# STM32L4P5 register map
File version: 1.8
CPU: CM4 r0p1, little endian, MPU, FPU, 4 interrupt priority bits
Registers are 32-bit, read-write, reset 0x0 unless marked. A register's access mark holds for its fields unless they carry their own. Offsets are from the block's base; [hi:lo] are bit positions; {n}, {i} and the like mark numbered series; 'fields as' and 'values as' point back to an identical list.

## GPIOA — General-purpose I/Os
Base 0x48000000
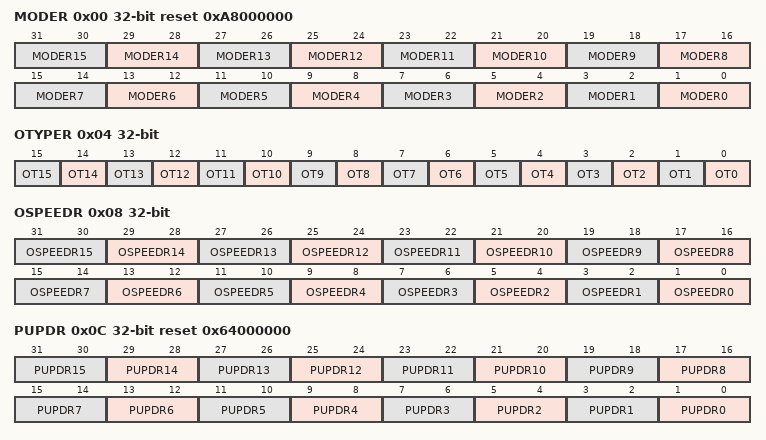
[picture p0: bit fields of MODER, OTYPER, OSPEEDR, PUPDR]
0x00 MODER reset 0xA8000000 — GPIO port mode register
  [2n+1:2n] MODER{n} (n=0..15) — Port x configuration pin {n}
    0=Input mode (reset state); 1=Output (General purpose output mode); 2=Alternate function mode; 3=Analog mode
0x04 OTYPER — GPIO port output type register
  [n] OT{n} (n=0..15) — Port x configuration pin {n}
    0=PushPull (Output push-pull (reset state)); 1=OpenDrain (Output open-drain)
0x08 OSPEEDR — GPIO port output speed register
  [2n+1:2n] OSPEEDR{n} (n=0..15) — Port x configuration pin {n}
    0=LowSpeed; 1=MediumSpeed; 2=HighSpeed; 3=VeryHighSpeed
0x0C PUPDR reset 0x64000000 — GPIO port pull-up/pull-down register
  [2n+1:2n] PUPDR{n} (n=0..15) — Port x configuration pin {n}
    0=Floating (No pull-up, pull-down); 1=PullUp; 2=PullDown
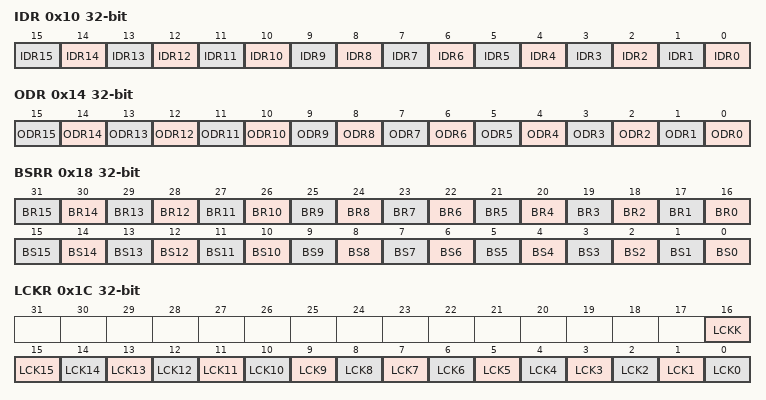
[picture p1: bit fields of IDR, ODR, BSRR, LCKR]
0x10 IDR ro — GPIO port input data register
  [n] IDR{n} (n=0..15) — Port input data pin {n}
    0=Low (Input is logic low); 1=High (Input is logic high)
0x14 ODR — GPIO port output data register
  [n] ODR{n} (n=0..15) — Port output data pin {n}
    0=Low (Set output to logic low); 1=High (Set output to logic high)
0x18 BSRR wo — GPIO port bit set/reset register
  [n+16] BR{n} (n=0..15) — Port x reset pin {n}
    1=Resets the corresponding ODRx bit
  [n] BS{n} (n=0..15) — Port x set pin {n}
    1=Set (Sets the corresponding ODRx bit)
0x1C LCKR — GPIO port configuration lock register
  [16] LCKK — Port x lock bit y (y= 0..15)
    0=NotActive (Port configuration lock key not active); 1=Active (Port configuration lock key active)
  [n] LCK{n} (n=0..15) — Port x lock pin {n}
    0=Unlocked (Port configuration not locked); 1=Locked (Port configuration locked)
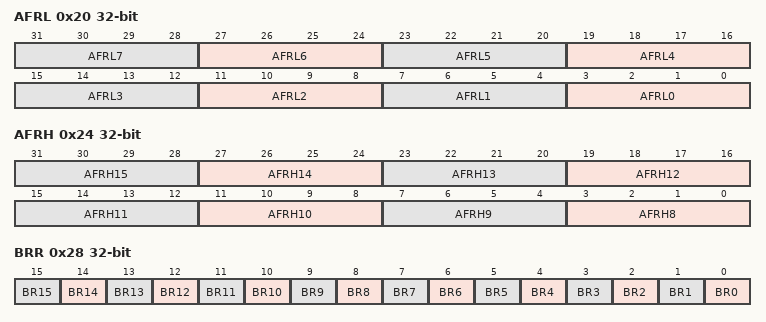
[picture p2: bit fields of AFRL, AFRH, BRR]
0x20 AFRL — GPIO alternate function low register
  [3:0] AFR{x} (x=L0,L1,L2,L3,L4,L5,L6,L7; step 4) — Alternate function selection for port x bit y (y = 0..7)
    {v}=AF{v} (v=0..15)
0x24 AFRH — GPIO alternate function high register
  [3:0] AFR{x} (x=H8,H9,H10,H11,H12,H13,H14,H15; step 4) — Alternate function selection for port x bit y (y = 8..15)
    {v}=AF{v} (v=0..15)
0x28 BRR wo — GPIO port bit reset register
  [n] BR{n} (n=0..15) — Port x reset pin {n}
    0=No action on the corresponding ODx bit; 1=Reset the ODx bit

## GPIOB — General-purpose I/Os
Base 0x48000400
Registers as GPIOA; these are added or differ:
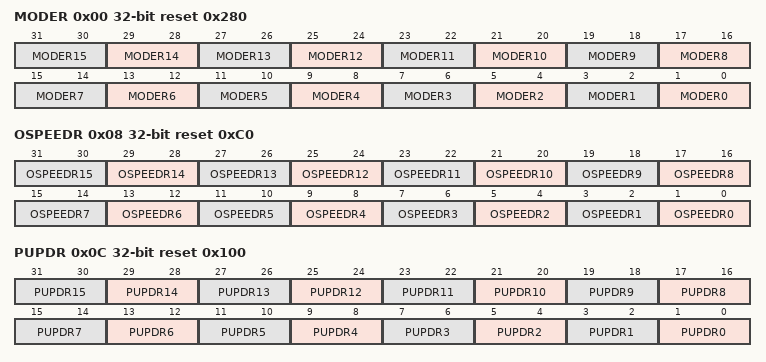
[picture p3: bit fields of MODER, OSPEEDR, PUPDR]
0x00 MODER reset 0x280 — GPIO port mode register
  [2n+1:2n] MODER{n} (n=0..15) — Port x configuration pin {n}
    0=Input mode (reset state); 1=Output (General purpose output mode); 2=Alternate function mode; 3=Analog mode
0x08 OSPEEDR reset 0xC0 — GPIO port output speed register
  [2n+1:2n] OSPEEDR{n} (n=0..15) — Port x configuration pin {n}
    0=LowSpeed; 1=MediumSpeed; 2=HighSpeed; 3=VeryHighSpeed
0x0C PUPDR reset 0x100 — GPIO port pull-up/pull-down register
  [2n+1:2n] PUPDR{n} (n=0..15) — Port x configuration pin {n}
    0=Floating (No pull-up, pull-down); 1=PullUp; 2=PullDown

## GPIOC — General-purpose I/Os
Base 0x48000800
Same registers: GPIOD 0x48000C00, GPIOE 0x48001000, GPIOF 0x48001400, GPIOG 0x48001800, GPIOH 0x48001C00, GPIOI 0x48002000
Registers as GPIOA; these are added or differ:
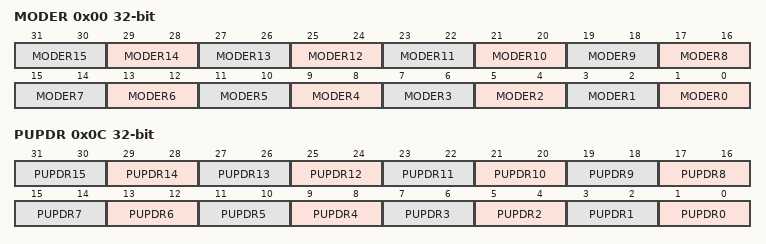
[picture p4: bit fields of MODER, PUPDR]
0x00 MODER — GPIO port mode register
  [2n+1:2n] MODER{n} (n=0..15) — Port x configuration pin {n}
    0=Input mode (reset state); 1=Output (General purpose output mode); 2=Alternate function mode; 3=Analog mode
0x0C PUPDR — GPIO port pull-up/pull-down register
  [2n+1:2n] PUPDR{n} (n=0..15) — Port x configuration pin {n}
    0=Floating (No pull-up, pull-down); 1=PullUp; 2=PullDown

## EXTI — External interrupt/event controller
Base 0x40010400
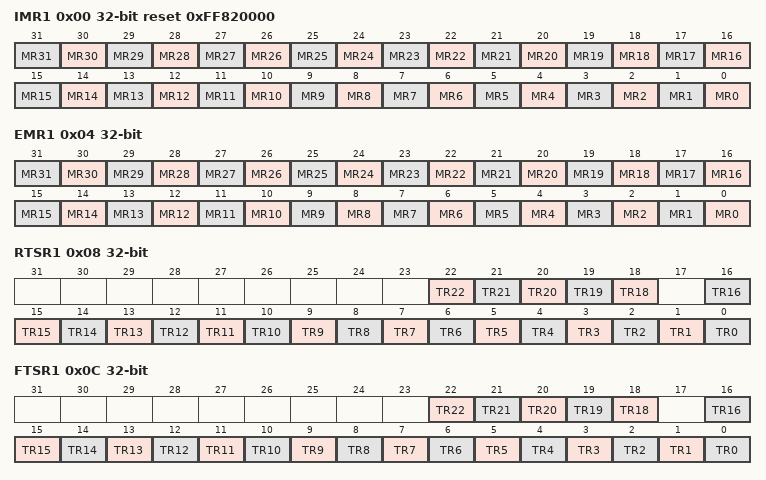
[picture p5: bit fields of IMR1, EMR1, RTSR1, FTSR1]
0x00 IMR1 reset 0xFF820000 — Interrupt mask register
  [all] fields
    0=Masked (Interrupt request line is masked); 1=Unmasked (Interrupt request line is unmasked)
  [n] MR{n} (n=0..31) — Interrupt Mask on line {n}
0x04 EMR1 — Event mask register
  [all] fields
    0=Masked (Event request line is masked); 1=Unmasked (Event request line is unmasked)
  [n] MR{n} (n=0..31) — Event Mask on line {n}
0x08 RTSR1 — Rising Trigger selection register
  [all] fields
    0=Disabled (Rising edge trigger is disabled); 1=Enabled (Rising edge trigger is enabled)
  [n] TR{n} (n=18..22) — Rising trigger event configuration of line {n}
  [n] TR{n} (n=0..16) — Rising trigger event configuration of line {n}
0x0C FTSR1 — Falling Trigger selection register
  [all] fields
    0=Disabled (Falling edge trigger is disabled); 1=Enabled (Falling edge trigger is enabled)
  [n] TR{n} (n=18..22) — Falling trigger event configuration of line {n}
  [n] TR{n} (n=0..16) — Falling trigger event configuration of line {n}
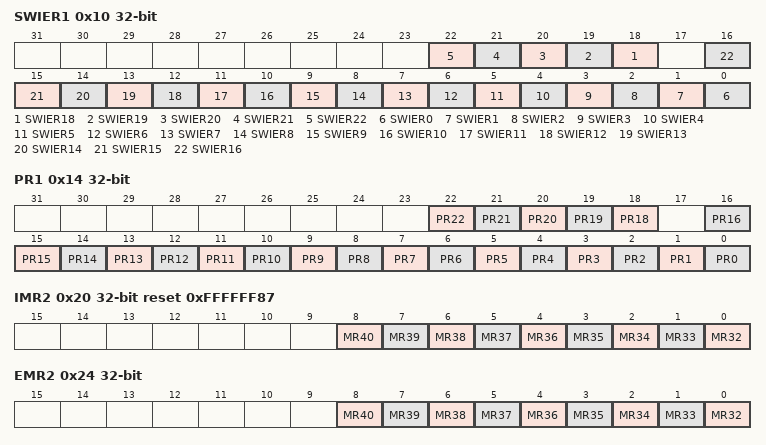
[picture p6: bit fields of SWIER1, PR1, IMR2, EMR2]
0x10 SWIER1 — Software interrupt event register
  [all] fields
    on write: 1=Pend (Generates an interrupt request)
  [n] SWIER{n} (n=18..22) — Software Interrupt on line {n}
  [n] SWIER{n} (n=0..16) — Software Interrupt on line {n}
0x14 PR1 — Pending register
  [all] fields
    on read: 0=NotPending (No trigger request occurred); 1=Pending (Selected trigger request occurred) | on write: 1=Clears pending bit
  [n] PR{n} write-1-clears (n=18..22) — Pending bit {n}
  [n] PR{n} write-1-clears (n=0..16) — Pending bit {n}
0x20 IMR2 reset 0xFFFFFF87 — Interrupt mask register
  [all] fields
    values as the fields of IMR1
  [n-32] MR{n} (n=32..40) — Interrupt Mask on external/internal line {n}
0x24 EMR2 — Event mask register
  [all] fields
    values as the fields of EMR1
  [n-32] MR{n} (n=32..40) — Event mask on external/internal line {n}
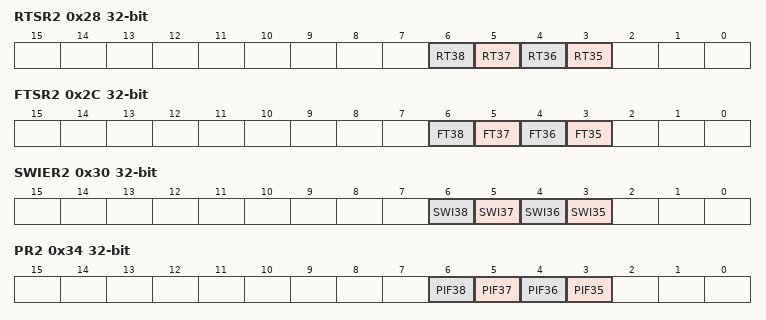
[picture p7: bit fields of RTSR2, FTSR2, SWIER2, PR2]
0x28 RTSR2 — Rising Trigger selection register
  [all] fields
    values as the fields of RTSR1
  [n-32] RT{n} (n=35..38) — Rising trigger event configuration bit of line {n}
0x2C FTSR2 — Falling Trigger selection register
  [all] fields
    values as the fields of FTSR1
  [n-32] FT{n} (n=35..38) — Falling trigger event configuration bit of line {n}
0x30 SWIER2 — Software interrupt event register
  [all] fields
    on write: 1=Pend (Generates an interrupt request)
  [n-32] SWI{n} (n=35..38) — Software interrupt on line {n}
0x34 PR2 — Pending register
  [all] fields
    values as the fields of PR1
  [n-32] PIF{n} write-1-clears (n=35..38) — Pending interrupt flag on line {n}
